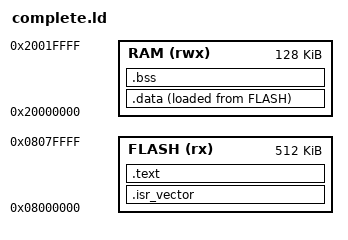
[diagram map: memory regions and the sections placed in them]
MEMORY
{
    FLASH (rx) : ORIGIN = 0x08000000, LENGTH = 512K
    RAM (rwx)  : ORIGIN = 0x20000000, LENGTH = 128K
}

SECTIONS
{
    .isr_vector :
    {
        . = ALIGN(4);
        KEEP(*(.isr_vector))
        . = ALIGN(4);
    } > FLASH
    
    .text :
    {
        . = ALIGN(4);
        *(.text*)
        *(.rodata*)
        . = ALIGN(4);
    } > FLASH
    
    .data :
    {
        . = ALIGN(4);
        _sdata = .;
        *(.data*)
        . = ALIGN(4);
        _edata = .;
    } > RAM AT> FLASH
    
    .bss :
    {
        . = ALIGN(4);
        _sbss = .;
        __bss_start__ = _sbss;
        *(.bss*)
        *(COMMON)
        . = ALIGN(4);
        _ebss = .;
        __bss_end__ = _ebss;
    } > RAM
    
    /* Required symbols */
    end = .;
    _end = .;
    __end = .;
}
